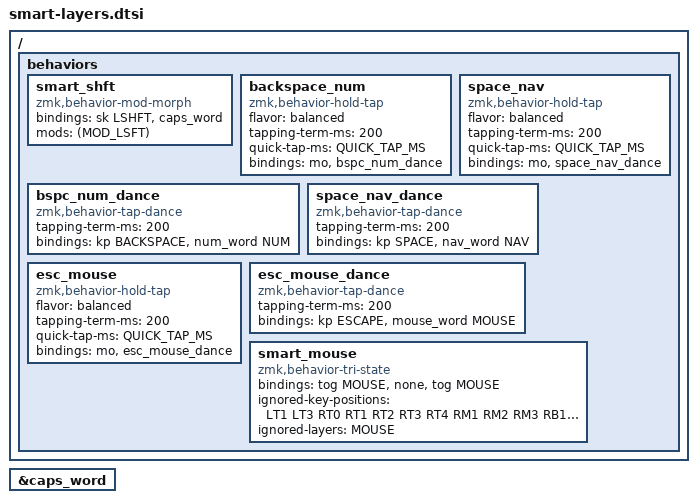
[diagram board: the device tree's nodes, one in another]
#include <behaviors/num_word.dtsi> // requires auto-layer module

// tap: sticky-shift | shift + tap/ double-tap: caps-word | hold: shift
ZMK_MOD_MORPH(smart_shft,
    bindings = <&sk LSHFT>, <&caps_word>;
    mods = <(MOD_LSFT)>;
)
&caps_word {  // mods deactivate caps-word, requires PR #1451
    /delete-property/ ignore-modifiers;
};

// tap: backspace | double-tap: num-word | hold: num-layer
#define BACKSPACE_NUM &backspace_num NUM DEF
ZMK_HOLD_TAP(backspace_num,
    flavor = "balanced";
    tapping-term-ms = <200>;
    quick-tap-ms = <QUICK_TAP_MS>;
    bindings = <&mo>, <&bspc_num_dance>;
)
ZMK_TAP_DANCE(bspc_num_dance,
    tapping-term-ms = <200>;
    bindings = <&kp BACKSPACE>, <&num_word NUM>;
)

// tap: space | double-tap: smart nav-layer | hold: nav-layer
#define SPACE_NAV &space_nav NAV DEF
ZMK_HOLD_TAP(space_nav,
    flavor = "balanced";
    tapping-term-ms = <200>;
    quick-tap-ms = <QUICK_TAP_MS>;
    bindings = <&mo>, <&space_nav_dance>;
)
ZMK_TAP_DANCE(space_nav_dance,
    tapping-term-ms = <200>;
    bindings = <&kp SPACE>, <&nav_word NAV>;
)

// tap: escape | double-tap: smart mouse-layer | hold: mouse-layer
#define MOUSESCAPE &esc_mouse MOUSE DEF
ZMK_HOLD_TAP(esc_mouse,
    flavor = "balanced";
    tapping-term-ms = <200>;
    quick-tap-ms = <QUICK_TAP_MS>;
    bindings = <&mo>, <&esc_mouse_dance>;
)
ZMK_TAP_DANCE(esc_mouse_dance,
    tapping-term-ms = <200>;
    bindings = <&kp ESCAPE>, <&mouse_word MOUSE>;
)

// smart-mouse, requires PR #1366
ZMK_TRI_STATE(smart_mouse,
    bindings = <&tog MOUSE>, <&none>, <&tog MOUSE>;
    ignored-key-positions = <LT1 LT3 RT0 RT1 RT2 RT3 RT4 RM1 RM2 RM3 RB1 RB2 RB3 RH0 RH1>;
    ignored-layers = <MOUSE>;
)
